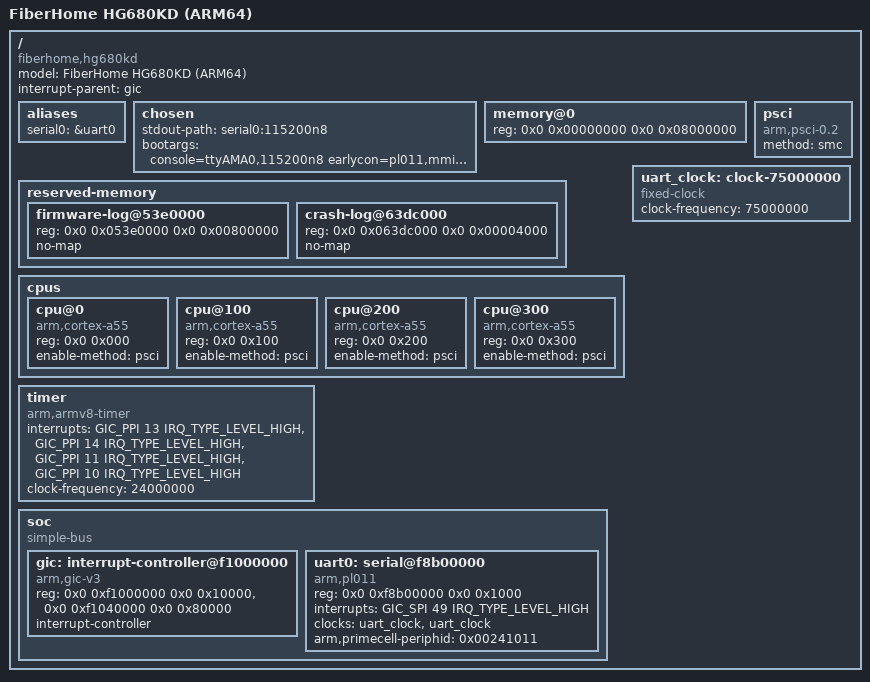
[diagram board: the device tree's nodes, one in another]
// SPDX-License-Identifier: (GPL-2.0-only OR BSD-2-Clause)
/dts-v1/;

#include <dt-bindings/interrupt-controller/arm-gic.h>

/ {
	model = "FiberHome HG680KD (ARM64)";
	compatible = "fiberhome,hg680kd", "hisilicon,hi3798mv320";
	#address-cells = <2>;
	#size-cells = <2>;
	interrupt-parent = <&gic>;

	aliases {
		serial0 = &uart0;
	};

	chosen {
		stdout-path = "serial0:115200n8";
		bootargs = "console=ttyAMA0,115200n8 earlycon=pl011,mmio32,0xf8b00000 ignore_loglevel";
	};

	memory@0 {
		device_type = "memory";
		/* Conservative 128 MiB bring-up window below the stock ATF load address. */
		reg = <0x0 0x00000000 0x0 0x08000000>;
	};

	reserved-memory {
		#address-cells = <2>;
		#size-cells = <2>;
		ranges;

		firmware-log@53e0000 {
			reg = <0x0 0x053e0000 0x0 0x00800000>;
			no-map;
		};

		crash-log@63dc000 {
			reg = <0x0 0x063dc000 0x0 0x00004000>;
			no-map;
		};
	};

	cpus {
		#address-cells = <2>;
		#size-cells = <0>;

		cpu@0 {
			device_type = "cpu";
			compatible = "arm,cortex-a55";
			reg = <0x0 0x000>;
			enable-method = "psci";
		};

		cpu@100 {
			device_type = "cpu";
			compatible = "arm,cortex-a55";
			reg = <0x0 0x100>;
			enable-method = "psci";
		};

		cpu@200 {
			device_type = "cpu";
			compatible = "arm,cortex-a55";
			reg = <0x0 0x200>;
			enable-method = "psci";
		};

		cpu@300 {
			device_type = "cpu";
			compatible = "arm,cortex-a55";
			reg = <0x0 0x300>;
			enable-method = "psci";
		};
	};

	psci {
		compatible = "arm,psci-0.2";
		method = "smc";
	};

	timer {
		compatible = "arm,armv8-timer";
		interrupts = <GIC_PPI 13 IRQ_TYPE_LEVEL_HIGH>,
			     <GIC_PPI 14 IRQ_TYPE_LEVEL_HIGH>,
			     <GIC_PPI 11 IRQ_TYPE_LEVEL_HIGH>,
			     <GIC_PPI 10 IRQ_TYPE_LEVEL_HIGH>;
		interrupt-names = "sec-phys", "phys", "virt", "hyp-phys";
		clock-frequency = <24000000>;
	};

	uart_clock: clock-75000000 {
		compatible = "fixed-clock";
		#clock-cells = <0>;
		clock-frequency = <75000000>;
	};

	soc {
		compatible = "simple-bus";
		#address-cells = <2>;
		#size-cells = <2>;
		ranges;

		gic: interrupt-controller@f1000000 {
			compatible = "arm,gic-v3";
			reg = <0x0 0xf1000000 0x0 0x10000>,
			      <0x0 0xf1040000 0x0 0x80000>;
			interrupt-controller;
			#address-cells = <0>;
			#interrupt-cells = <3>;
		};

		uart0: serial@f8b00000 {
			compatible = "arm,pl011", "arm,primecell";
			reg = <0x0 0xf8b00000 0x0 0x1000>;
			interrupts = <GIC_SPI 49 IRQ_TYPE_LEVEL_HIGH>;
			clocks = <&uart_clock>, <&uart_clock>;
			clock-names = "uartclk", "apb_pclk";
			arm,primecell-periphid = <0x00241011>;
		};
	};
};
